# STM32H5xx register map
File version: 0.3
CPU: CM33 r0p0, little endian, MPU, FPU, 4 interrupt priority bits
Registers are 32-bit, read-write, reset 0x0 unless marked. A register's access mark holds for its fields unless they carry their own. Offsets are from the block's base; lines under a group give offsets from that group; [hi:lo] are bit positions; {n}, {i} and the like mark numbered series; 'fields as' and 'values as' point back to an identical list; <NAME> marks a mode.

## Memory map
0x40002C00 WWDG size 0x400 — System window watchdog
0x40003000 IWDG size 0x400 — Independent watchdog
0x40005400 I2C1 size 0x400 — Inter-integrated circuit
0x40006000 CRS size 0x400 — Clock recovery system
0x4000A400 FDCAN1 size 0x400
0x40015400 SAI1 size 0x400 — Serial audio interface
0x40021000 CORDIC size 0x400 — CORDIC Co-processor
0x40021400 FMAC size 0x400 — Filter Math Accelerator
0x40023000 CRC size 0x400 — Cyclic redundancy check calculation unit
0x40032400 GTZC1_TZSC size 0x400
0x42020000 GPIOA size 0x400 — General-purpose I/Os
0x42020400 GPIOB size 0x400 — General-purpose I/Os
0x42020800 GPIOC size 0x400 — General-purpose I/Os
0x42020C00 GPIOD size 0x400
0x42021000 GPIOE size 0x400
0x42021400 GPIOF size 0x400
0x42021800 GPIOG size 0x400
0x42021C00 GPIOH size 0x400 — General-purpose I/Os
0x42022000 GPIOI size 0x400 — General-purpose I/Os
0x420C2000 PKA size 0x2000 — Private key accelerator
0x46007400 VREFBUF size 0x400 — Voltage reference buffer
0x50002C00 SEC_WWDG size 0x400
0x50003000 SEC_IWDG size 0x400
0x50005400 SEC_I2C1 size 0x400
0x50006000 SEC_CRS size 0x400
0x5000A400 SEC_FDCAN1 size 0x400
0x50015400 SEC_SAI1 size 0x400
0x50021000 SEC_CORDIC size 0x400
0x50021400 SEC_FMAC size 0x400
0x50023000 SEC_CRC size 0x400
0x50032400 SEC_GTZC1_TZSC size 0x400
0x52020000 SEC_GPIOA size 0x400
0x52020400 SEC_GPIOB size 0x400
0x52020800 SEC_GPIOC size 0x400
0x52020C00 SEC_GPIOD size 0x400
0x52021000 SEC_GPIOE size 0x400
0x52021400 SEC_GPIOF size 0x400
0x52021800 SEC_GPIOG size 0x400
0x52021C00 SEC_GPIOH size 0x400
0x52022000 SEC_GPIOI size 0x400
0x520C2000 SEC_PKA size 0x2000
0x56007400 SEC_VREFBUF size 0x400

## Interrupts
0 WWDG — Window Watchdog interrupt
55 I2C1_EV (I2C1) — I2C1 event interrupt
56 I2C1_ER (I2C1) — I2C1 error interrupt
71 TIM17 (FDCAN1) — TIM17 global interrupt
90 SAI1 — SAI1 global interrupt
97 PKA — PKA global interrupt
123 Cordic (CORDIC) — Cordic interrupt
124 FMAC — FMAC interrupt

## CRC — Cyclic redundancy check calculation unit
Base 0x40023000
Same registers: SEC_CRC 0x50023000
0x00 DR reset 0xFFFFFFFF — Data register
  [31:0] DR — Data register bits
0x04 IDR — Independent data register
  [31:0] IDR — General-purpose 8-bit data register bits
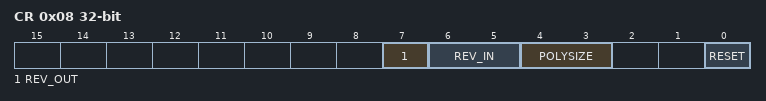
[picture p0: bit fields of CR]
0x08 CR — Control register
  [7] REV_OUT — Reverse output data
  [6:5] REV_IN — Reverse input data
  [4:3] POLYSIZE — Polynomial size
  [0] RESET — RESET bit
0x10 INIT reset 0xFFFFFFFF — Initial CRC value
  [31:0] CRC_INIT — Programmable initial CRC value
0x14 POL reset 0x4C11DB7 — polynomial
  [31:0] POL — Programmable polynomial

## CRS — Clock recovery system
Base 0x40006000
Same registers: SEC_CRS 0x50006000
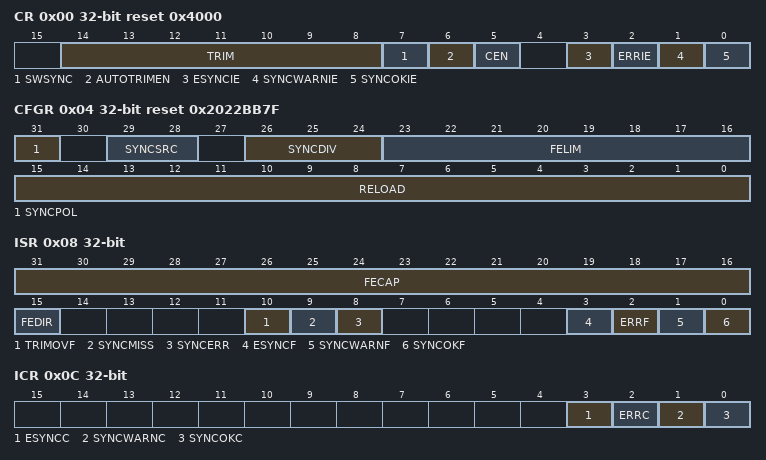
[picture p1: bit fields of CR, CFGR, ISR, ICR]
0x00 CR reset 0x4000 — control register
  [14:8] TRIM — HSI48 oscillator smooth trimming
  [7] SWSYNC — Generate software SYNC event
  [6] AUTOTRIMEN — Automatic trimming enable
  [5] CEN — Frequency error counter enable
  [3] ESYNCIE — Expected SYNC interrupt enable
  [2] ERRIE — Synchronization or trimming error interrupt enable
  [1] SYNCWARNIE — SYNC warning interrupt enable
  [0] SYNCOKIE — SYNC event OK interrupt enable
0x04 CFGR reset 0x2022BB7F — configuration register
  [31] SYNCPOL — SYNC polarity selection
  [29:28] SYNCSRC — SYNC signal source selection
  [26:24] SYNCDIV — SYNC divider
  [23:16] FELIM — Frequency error limit
  [15:0] RELOAD — Counter reload value
0x08 ISR ro — interrupt and status register
  [31:16] FECAP — Frequency error capture
  [15] FEDIR — Frequency error direction
  [10] TRIMOVF — Trimming overflow or underflow
  [9] SYNCMISS — SYNC missed
  [8] SYNCERR — SYNC error
  [3] ESYNCF — Expected SYNC flag
  [2] ERRF — Error flag
  [1] SYNCWARNF — SYNC warning flag
  [0] SYNCOKF — SYNC event OK flag
0x0C ICR — interrupt flag clear register
  [3] ESYNCC — Expected SYNC clear flag
  [2] ERRC — Error clear flag
  [1] SYNCWARNC — SYNC warning clear flag
  [0] SYNCOKC — SYNC event OK clear flag

## Notices in the file
Copyright (c) 2021 STMicroelectronics.
SPDX-License-Identifier: Apache-2.0
Licensed under the Apache License, Version 2.0 (the "License");
you may not use this file except in compliance with the License.
You may obtain a copy of the License at
http://www.apache.org/licenses/LICENSE-2.0
Unless required by applicable law or agreed to in writing, software
distributed under the License is distributed on an "AS IS" BASIS,
WITHOUT WARRANTIES OR CONDITIONS OF ANY KIND, either express or implied.
See the License for the specific language governing permissions and
limitations under the License.
